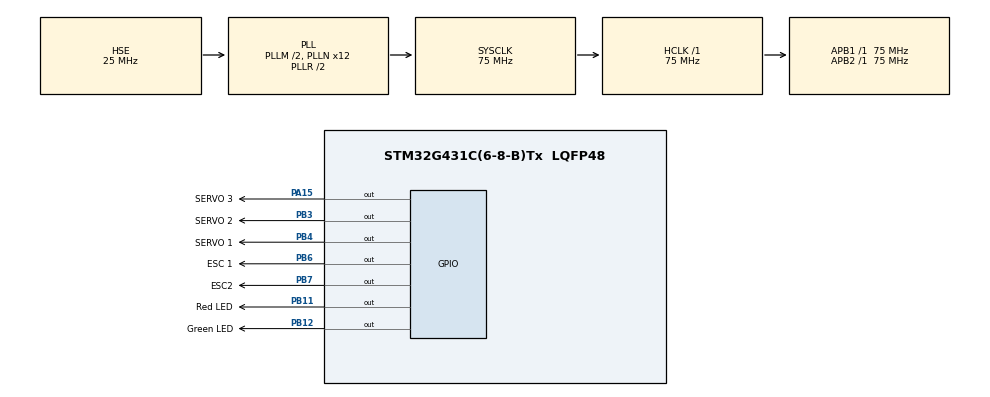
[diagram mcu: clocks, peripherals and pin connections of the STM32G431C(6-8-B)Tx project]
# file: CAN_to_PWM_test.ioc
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Mcu.Family=STM32G4
Mcu.Name=STM32G431C(6-8-B)Tx
Mcu.Package=LQFP48
NVIC.PriorityGroup=NVIC_PRIORITYGROUP_4
PA13.Mode=Serial_Wire
PA13.Signal=SYS_JTMS-SWDIO
PA14.Mode=Serial_Wire
PA14.Signal=SYS_JTCK-SWCLK
PA15.GPIO_Label=SERVO 3
PA15.Signal=GPIO_Output
PB11.GPIO_Label=Red LED
PB11.Signal=GPIO_Output
PB12.GPIO_Label=Green LED
PB12.Signal=GPIO_Output
PB3.GPIO_Label=SERVO 2
PB3.Signal=GPIO_Output
PB4.GPIO_Label=SERVO 1
PB4.Signal=GPIO_Output
PB6.GPIO_Label=ESC 1
PB6.Signal=GPIO_Output
PB7.GPIO_Label=ESC2
PB7.Signal=GPIO_Output
PF0-OSC_IN.Mode=HSE-External-Oscillator
PF0-OSC_IN.Signal=RCC_OSC_IN
PF1-OSC_OUT.Mode=HSE-External-Oscillator
PF1-OSC_OUT.Signal=RCC_OSC_OUT
ProjectManager.HeapSize=0x200
ProjectManager.StackSize=0x400
ProjectManager.TargetToolchain=CMake
RCC.ADC12Freq_Value=75000000
RCC.AHBFreq_Value=75000000
RCC.APB1Freq_Value=75000000
RCC.APB1TimFreq_Value=75000000
RCC.APB2Freq_Value=75000000
RCC.APB2TimFreq_Value=75000000
RCC.CortexFreq_Value=75000000
RCC.EXTERNAL_CLOCK_VALUE=12288000
RCC.HCLKFreq_Value=75000000
RCC.HSE_VALUE=25000000
RCC.HSI48_VALUE=48000000
RCC.HSI_VALUE=16000000
RCC.LSE_VALUE=32768
RCC.PLLM=RCC_PLLM_DIV2
RCC.PLLN=12
RCC.PLLSourceVirtual=RCC_PLLSOURCE_HSE
RCC.SYSCLKFreq_VALUE=75000000
RCC.SYSCLKSource=RCC_SYSCLKSOURCE_PLLCLK
RCC.USBFreq_Value=75000000
RCC.VCOOutputFreq_Value=150000000
VP_SYS_VS_DBSignals.Mode=DisableDeadBatterySignals
board=custom

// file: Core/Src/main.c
/* USER CODE BEGIN Header */
/**
  ******************************************************************************
  * @file           : main.c
  * @brief          : Main program body
  ******************************************************************************
  * @attention
  *
  * Copyright (c) 2026 STMicroelectronics.
  * All rights reserved.
  *
  * This software is licensed under terms that can be found in the LICENSE file
  * in the root directory of this software component.
  * If no LICENSE file comes with this software, it is provided AS-IS.
  *
  ******************************************************************************
  */
/* USER CODE END Header */
#include "main.h"
#include "stm32g4xx_hal.h"
#include "stm32g4xx_hal_gpio.h"

void SystemClock_Config(void);
static void MX_GPIO_Init(void);

int main(void)
{

  /* MCU Configuration--------------------------------------------------------*/

  /* Reset of all peripherals, Initializes the Flash interface and the Systick. */
  HAL_Init();

  /* Configure the system clock */
  SystemClock_Config();

  /* Initialize all configured peripherals */
  MX_GPIO_Init();

  /* Infinite loop */
  /* USER CODE BEGIN WHILE */
  while (1)
  {
    HAL_GPIO_TogglePin(GPIOB, GPIO_PIN_6); // ESC 1
    HAL_GPIO_TogglePin(GPIOB, GPIO_PIN_7); // ESC 2
    HAL_GPIO_TogglePin(GPIOB, GPIO_PIN_4); // SERVO 1
    HAL_GPIO_TogglePin(GPIOB, GPIO_PIN_3); // SERVO 2
    HAL_GPIO_TogglePin(GPIOA, GPIO_PIN_15); // SERVO 3
    HAL_GPIO_TogglePin(GPIOB, GPIO_PIN_11); // RED LED
    HAL_GPIO_TogglePin(GPIOB, GPIO_PIN_12); // Green LED

    HAL_Delay(10000);
    /* USER CODE END WHILE */

  }
}

void SystemClock_Config(void)
{
  RCC_OscInitTypeDef RCC_OscInitStruct = {0};
  RCC_ClkInitTypeDef RCC_ClkInitStruct = {0};

  /** Configure the main internal regulator output voltage
  */
  HAL_PWREx_ControlVoltageScaling(PWR_REGULATOR_VOLTAGE_SCALE1);

  /** Initializes the RCC Oscillators according to the specified parameters
  * in the RCC_OscInitTypeDef structure.
  */
  RCC_OscInitStruct.OscillatorType = RCC_OSCILLATORTYPE_HSE;
  RCC_OscInitStruct.HSEState = RCC_HSE_ON;
  RCC_OscInitStruct.PLL.PLLState = RCC_PLL_ON;
  RCC_OscInitStruct.PLL.PLLSource = RCC_PLLSOURCE_HSE;
  RCC_OscInitStruct.PLL.PLLM = RCC_PLLM_DIV2;
  RCC_OscInitStruct.PLL.PLLN = 12;
  RCC_OscInitStruct.PLL.PLLP = RCC_PLLP_DIV2;
  RCC_OscInitStruct.PLL.PLLQ = RCC_PLLQ_DIV2;
  RCC_OscInitStruct.PLL.PLLR = RCC_PLLR_DIV2;
  if (HAL_RCC_OscConfig(&RCC_OscInitStruct) != HAL_OK)
  {
    Error_Handler();
  }

  /** Initializes the CPU, AHB and APB buses clocks
  */
  RCC_ClkInitStruct.ClockType = RCC_CLOCKTYPE_HCLK|RCC_CLOCKTYPE_SYSCLK
                              |RCC_CLOCKTYPE_PCLK1|RCC_CLOCKTYPE_PCLK2;
  RCC_ClkInitStruct.SYSCLKSource = RCC_SYSCLKSOURCE_PLLCLK;
  RCC_ClkInitStruct.AHBCLKDivider = RCC_SYSCLK_DIV1;
  RCC_ClkInitStruct.APB1CLKDivider = RCC_HCLK_DIV1;
  RCC_ClkInitStruct.APB2CLKDivider = RCC_HCLK_DIV1;

  if (HAL_RCC_ClockConfig(&RCC_ClkInitStruct, FLASH_LATENCY_2) != HAL_OK)
  {
    Error_Handler();
  }
}

static void MX_GPIO_Init(void)
{
  GPIO_InitTypeDef GPIO_InitStruct = {0};

  /* GPIO Ports Clock Enable */
  __HAL_RCC_GPIOF_CLK_ENABLE();
  __HAL_RCC_GPIOB_CLK_ENABLE();
  __HAL_RCC_GPIOA_CLK_ENABLE();

  /*Configure GPIO pin Output Level */
  HAL_GPIO_WritePin(GPIOB, Red_LED_Pin|Green_LED_Pin|SERVO_2_Pin|SERVO_1_Pin
                          |ESC_1_Pin|ESC2_Pin, GPIO_PIN_RESET);

  /*Configure GPIO pin Output Level */
  HAL_GPIO_WritePin(SERVO_3_GPIO_Port, SERVO_3_Pin, GPIO_PIN_RESET);

  /*Configure GPIO pins : Red_LED_Pin Green_LED_Pin SERVO_2_Pin SERVO_1_Pin
                           ESC_1_Pin ESC2_Pin */
  GPIO_InitStruct.Pin = Red_LED_Pin|Green_LED_Pin|SERVO_2_Pin|SERVO_1_Pin
                          |ESC_1_Pin|ESC2_Pin;
  GPIO_InitStruct.Mode = GPIO_MODE_OUTPUT_PP;
  GPIO_InitStruct.Pull = GPIO_NOPULL;
  GPIO_InitStruct.Speed = GPIO_SPEED_FREQ_LOW;
  HAL_GPIO_Init(GPIOB, &GPIO_InitStruct);

  /*Configure GPIO pin : SERVO_3_Pin */
  GPIO_InitStruct.Pin = SERVO_3_Pin;
  GPIO_InitStruct.Mode = GPIO_MODE_OUTPUT_PP;
  GPIO_InitStruct.Pull = GPIO_NOPULL;
  GPIO_InitStruct.Speed = GPIO_SPEED_FREQ_LOW;
  HAL_GPIO_Init(SERVO_3_GPIO_Port, &GPIO_InitStruct);

}

void Error_Handler(void)
{
  __disable_irq();
  while (1)
  {
  }
}
